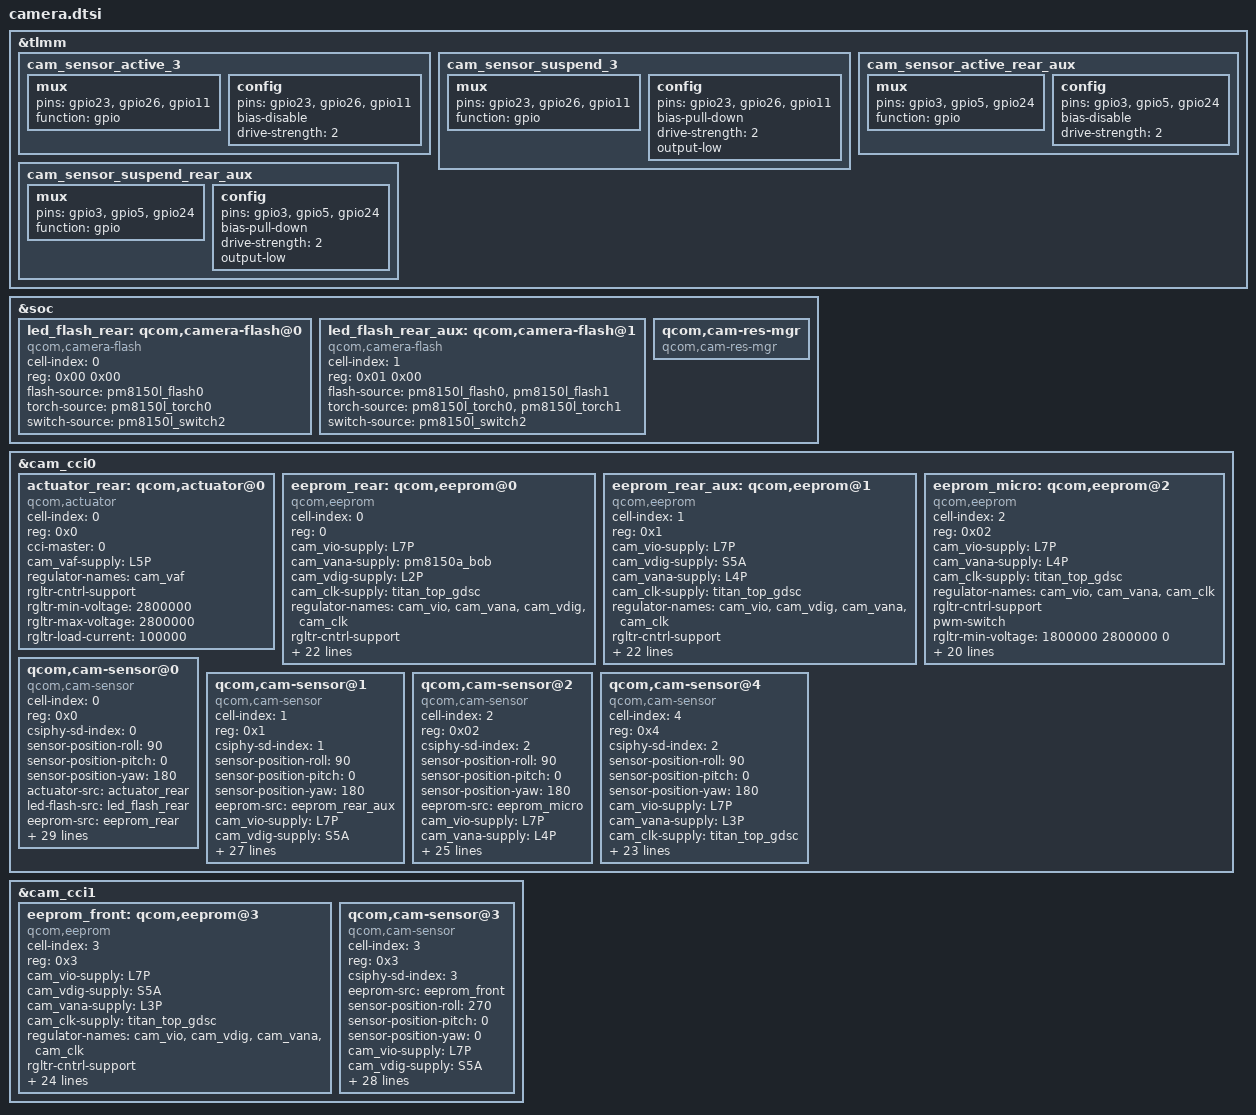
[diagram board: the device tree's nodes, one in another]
#include <dt-bindings/clock/qcom,camcc-lito.h>

&tlmm {
//20M
	/delete-node/ cam_sensor_active_3;
	/delete-node/ cam_sensor_suspend_3;
	/delete-node/ cam_sensor_active_rear_aux;
	/delete-node/ cam_sensor_suspend_rear_aux;
	cam_sensor_active_3: cam_sensor_active_3 {
		/* RESET FRONT */
		mux {
			pins = "gpio23", "gpio26", "gpio11";
			function = "gpio";
		};

		config {
			pins = "gpio23", "gpio26", "gpio11";
			bias-disable; /* No PULL */
			drive-strength = <2>; /* 2 MA */
		};
	};

	cam_sensor_suspend_3: cam_sensor_suspend_3 {
		/* RESET FRONT */
		mux {
			pins = "gpio23", "gpio26", "gpio11";
			function = "gpio";
		};

		config {
			pins = "gpio23", "gpio26", "gpio11";
			bias-pull-down; /* PULL DOWN */
			drive-strength = <2>; /* 2 MA */
			output-low;
		};
	};
//8M
		cam_sensor_active_rear_aux: cam_sensor_active_rear_aux {
			/* RESET REARAUX,DVDD ELDO */
			mux {
				pins = "gpio3", "gpio5", "gpio24";
				function = "gpio";
			};

			config {
				pins = "gpio3", "gpio5", "gpio24";
				bias-disable; /* No PULL */
				drive-strength = <2>; /* 2 MA */
			};
		};

		cam_sensor_suspend_rear_aux: cam_sensor_suspend_rear_aux {
			/* RESET REARAUX,DVDD ELDO */
			mux {
				pins = "gpio3", "gpio5", "gpio24";
				function = "gpio";
			};

			config {
				pins = "gpio3", "gpio5", "gpio24";
				bias-pull-down; /* PULL DOWN */
				drive-strength = <2>; /* 2 MA */
				output-low;
			};
		};
};

&soc {
	led_flash_rear: qcom,camera-flash@0 {
		cell-index = <0>;
		reg = <0x00 0x00>;
		compatible = "qcom,camera-flash";
		flash-source = <&pm8150l_flash0>;
		torch-source = <&pm8150l_torch0>;
		switch-source = <&pm8150l_switch2>;
	};

	led_flash_rear_aux: qcom,camera-flash@1 {
		cell-index = <1>;
		reg = <0x01 0x00>;
		compatible = "qcom,camera-flash";
		flash-source = <&pm8150l_flash0 &pm8150l_flash1>;
		torch-source = <&pm8150l_torch0 &pm8150l_torch1>;
		switch-source = <&pm8150l_switch2>;
	};

	qcom,cam-res-mgr {
		compatible = "qcom,cam-res-mgr";
		status = "ok";
	};
	
};

&cam_cci0 {
	actuator_rear: qcom,actuator@0 {
		cell-index = <0>;
		reg = <0x0>;
		compatible = "qcom,actuator";
		cci-master = <0>;
		cam_vaf-supply = <&L5P>;
		regulator-names = "cam_vaf";
		rgltr-cntrl-support;
		rgltr-min-voltage = <2800000>;
		rgltr-max-voltage = <2800000>;
		rgltr-load-current = <100000>;
		status = "ok";
	};

	eeprom_rear: qcom,eeprom@0 {
		cell-index = <0>;
		reg = <0>;
		compatible = "qcom,eeprom";
		cam_vio-supply = <&L7P>;
		cam_vana-supply = <&pm8150a_bob>;
		cam_vdig-supply = <&L2P>;
		cam_clk-supply = <&titan_top_gdsc>;
		regulator-names = "cam_vio","cam_vana","cam_vdig",
			"cam_clk";
		rgltr-cntrl-support;
		pwm-switch;
		rgltr-min-voltage = <1800000 3008000 1104000 0>;
		rgltr-max-voltage = <1800000 3960000 1104000 0>;
		rgltr-load-current = <0 2000000 105000 0>;
		gpio-no-mux = <0>;
		pinctrl-names = "cam_default", "cam_suspend";
		pinctrl-0 = <&cam_sensor_mclk0_active
				&cam_sensor_active_rear>;
		pinctrl-1 = <&cam_sensor_mclk0_suspend
				&cam_sensor_suspend_rear>;
		gpios = <&tlmm 13 0>,
			<&tlmm 30 0>,
			<&tlmm 0 0>,
			<&tlmm 63 0>;
		gpio-reset = <1>;
		gpio-vana = <2>;
		gpio-custom1 = <3>;
		gpio-req-tbl-num = <0 1 2 3>;
		gpio-req-tbl-flags = <1 0 0 0>;
		gpio-req-tbl-label = "CAMIF_MCLK0",
					"CAM_RESET0",
					"CAM_VANA0",
					"CAM_CUSTOM1";
		sensor-mode = <0>;
		cci-master = <0>;
		status = "ok";
		clocks = <&camcc CAM_CC_MCLK0_CLK>;
		clock-names = "cam_clk";
		clock-cntl-level = "turbo";
		clock-rates = <24000000>;
	};
	eeprom_rear_aux: qcom,eeprom@1 {
		cell-index = <1>;
		reg = <0x1>;
		compatible = "qcom,eeprom";
		cam_vio-supply = <&L7P>;
		cam_vdig-supply = <&S5A>;
		cam_vana-supply = <&L4P>;
		cam_clk-supply = <&titan_top_gdsc>;
		regulator-names ="cam_vio","cam_vdig","cam_vana","cam_clk";
		rgltr-cntrl-support;
		pwm-switch;
		rgltr-min-voltage =  <1800000 2000000 2800000 0>;
		rgltr-max-voltage =  <1800000 2000000 2800000 0>;
		rgltr-load-current = <120000  120000  80000   0>;
		gpio-no-mux = <0>;
		pinctrl-names = "cam_default", "cam_suspend";
		pinctrl-0 = <&cam_sensor_mclk1_active
				&cam_sensor_active_rear_aux>;
		pinctrl-1 = <&cam_sensor_mclk1_suspend
				&cam_sensor_suspend_rear_aux>;
		gpios = <&tlmm 14 0>,
			<&tlmm  3 0>,
			<&tlmm  5 0>,
			<&tlmm 24 0>;
		gpio-standby = <1>;
		gpio-vdig = <2>;
		gpio-reset = <3>;
		gpio-req-tbl-num = <0 1 2 3>;
		gpio-req-tbl-flags = <1 0 0 0>;
		gpio-req-tbl-label = "CAMIF_MCLK1",
		"CAM_STANDBY1",
		"CAM_VDIG1",
		"CAM_RESET1";
		sensor-mode = <0>;
		cci-master = <0>;
		status = "ok";
		clocks = <&camcc CAM_CC_MCLK1_CLK>;
		clock-names = "cam_clk";
		clock-cntl-level = "turbo";
		clock-rates = <19200000>;
	};
	eeprom_micro: qcom,eeprom@2 {
		cell-index = <2>;
		reg = <0x02>;
		compatible = "qcom,eeprom";
		cam_vio-supply = <&L7P>;
		cam_vana-supply = <&L4P>;
		cam_clk-supply = <&titan_top_gdsc>;
		regulator-names = "cam_vio", 
						  "cam_vana",
			              "cam_clk";
		rgltr-cntrl-support;
		pwm-switch;
		rgltr-min-voltage = <1800000 2800000 0>;
		rgltr-max-voltage = <1800000 2800000 0>;
		rgltr-load-current = <120000 80000 0>;
		gpio-no-mux = <0>;
		pinctrl-names = "cam_default", "cam_suspend";
		pinctrl-0 = <&cam_sensor_mclk4_active
				 &cam_sensor_active_rear_aux2>;
		pinctrl-1 = <&cam_sensor_mclk4_suspend
				 &cam_sensor_suspend_rear_aux2>;
		gpios = <&tlmm 25 0>,
			    <&tlmm 21 0>,
				<&tlmm 68 0>;
		gpio-reset = <1>;
		gpio-standby = <2>;
		gpio-req-tbl-num = <0 1 2>;
		gpio-req-tbl-flags = <1 0 0>;
		gpio-req-tbl-label = "CAMIF_MCLK2",
							  "CAM_RESET2",
							  "CAM_STANDBY2";
		sensor-mode = <0>;
		cci-device = <0>;
		cci-master = <1>;
		status = "ok";
		clocks = <&camcc CAM_CC_MCLK4_CLK>;
		clock-names = "cam_clk";
		clock-cntl-level = "turbo";
		clock-rates = <19200000>;
	};
	qcom,cam-sensor@0 {
		cell-index = <0>;
		compatible = "qcom,cam-sensor";
		reg = <0x0>;
		csiphy-sd-index = <0>;
		sensor-position-roll = <90>;
		sensor-position-pitch = <0>;
		sensor-position-yaw = <180>;
		actuator-src = <&actuator_rear>;
		led-flash-src = <&led_flash_rear>;
		eeprom-src = <&eeprom_rear>;
		cam_vio-supply = <&L7P>;
		cam_vana-supply = <&pm8150a_bob>;
		cam_vdig-supply = <&L2P>;
		cam_clk-supply = <&titan_top_gdsc>;
		regulator-names = "cam_vio","cam_vana","cam_vdig",
			"cam_clk";
		rgltr-cntrl-support;
		pwm-switch;
		rgltr-min-voltage = <1800000 3008000 1104000 0>;
		rgltr-max-voltage = <1800000 3960000 1104000 0>;
		rgltr-load-current = <0 2000000 105000 0>;
		gpio-no-mux = <0>;
		pinctrl-names = "cam_default", "cam_suspend";
		pinctrl-0 = <&cam_sensor_mclk0_active
				&cam_sensor_active_rear>;
		pinctrl-1 = <&cam_sensor_mclk0_suspend
				&cam_sensor_suspend_rear>;
		gpios = <&tlmm 13 0>,
			<&tlmm 30 0>,
			<&tlmm 0 0>,
			<&tlmm 63 0>;
		gpio-reset = <1>;
		gpio-vana = <2>;
		gpio-custom1 = <3>;
		gpio-req-tbl-num = <0 1 2 3>;
		gpio-req-tbl-flags = <1 0 0 0>;
		gpio-req-tbl-label = "CAMIF_MCLK0",
					"CAM_RESET0",
					"CAM_VANA0",
					"CAM_CUSTOM1";
		sensor-mode = <0>;
		cci-master = <0>;
		status = "ok";
		clocks = <&camcc CAM_CC_MCLK0_CLK>;
		clock-names = "cam_clk";
		clock-cntl-level = "turbo";
		clock-rates = <19200000>;
	};

	qcom,cam-sensor@1 {
		cell-index = <1>;
		compatible = "qcom,cam-sensor";
		reg = <0x1>;
		csiphy-sd-index = <1>;
		sensor-position-roll = <90>;
		sensor-position-pitch = <0>;
		sensor-position-yaw = <180>;
		eeprom-src = <&eeprom_rear_aux>;
		//led-flash-src = <&led_flash_rear_aux>;
		//actuator-src = <&actuator_rear_aux>;
		cam_vio-supply = <&L7P>;
		cam_vdig-supply = <&S5A>; 
		cam_vana-supply = <&L4P>; 
		cam_clk-supply = <&titan_top_gdsc>;
		regulator-names ="cam_vio","cam_vdig","cam_vana","cam_clk";
		rgltr-cntrl-support;
		pwm-switch;
		rgltr-min-voltage =  <1800000 2000000 2800000 0>;
		rgltr-max-voltage =  <1800000 2000000 2800000 0>;
		rgltr-load-current = <120000  120000  80000   0>;
		gpio-no-mux = <0>;
		pinctrl-names = "cam_default", "cam_suspend";
		pinctrl-0 = <&cam_sensor_mclk1_active
				&cam_sensor_active_rear_aux>;
		pinctrl-1 = <&cam_sensor_mclk1_suspend
				&cam_sensor_suspend_rear_aux>;
		gpios = <&tlmm 14 0>,
			<&tlmm  3 0>,
			<&tlmm  5 0>,
			<&tlmm 24 0>;
		gpio-standby = <1>;		
		gpio-vdig = <2>;
		gpio-reset = <3>;
		gpio-req-tbl-num = <0 1 2 3>;
		gpio-req-tbl-flags = <1 0 0 0>;
		gpio-req-tbl-label = "CAMIF_MCLK1",
		"CAM_STANDBY1",
		"CAM_VDIG1",
		"CAM_RESET1";
		sensor-mode = <0>;
		cci-master = <0>;
		status = "ok";
		clocks = <&camcc CAM_CC_MCLK1_CLK>;
		clock-names = "cam_clk";
		clock-cntl-level = "turbo";
		clock-rates = <19200000>;
	};
	qcom,cam-sensor@2 {
		cell-index = <2>;
		compatible = "qcom,cam-sensor";
		reg = <0x02>;
		csiphy-sd-index = <2>;
		sensor-position-roll = <90>;
		sensor-position-pitch = <0>;
		sensor-position-yaw = <180>;
		eeprom-src = <&eeprom_micro>;
		cam_vio-supply = <&L7P>;
		cam_vana-supply = <&L4P>;		
		cam_clk-supply = <&titan_top_gdsc>;
		regulator-names = "cam_vio", 
						  "cam_vana",
			              "cam_clk";
		rgltr-cntrl-support;
		pwm-switch;
		rgltr-min-voltage = <1800000 2800000 0>;
		rgltr-max-voltage = <1800000 2800000 0>;
		rgltr-load-current = <120000 80000 0>;
		gpio-no-mux = <0>;
		pinctrl-names = "cam_default", "cam_suspend";
		pinctrl-0 = <&cam_sensor_mclk4_active
				 &cam_sensor_active_rear_aux2>;
		pinctrl-1 = <&cam_sensor_mclk4_suspend
				 &cam_sensor_suspend_rear_aux2>;
		gpios = <&tlmm 25 0>,
			    <&tlmm 21 0>,
				<&tlmm 68 0>;
		gpio-reset = <1>;
		gpio-standby = <2>;
		gpio-req-tbl-num = <0 1 2>;
		gpio-req-tbl-flags = <1 0 0>;
		gpio-req-tbl-label = "CAMIF_MCLK2",
							  "CAM_RESET2",
							  "CAM_STANDBY2";
		sensor-mode = <0>;
		cci-device = <0>;
		cci-master = <1>;
		status = "ok";
		clocks = <&camcc CAM_CC_MCLK4_CLK>;
		clock-names = "cam_clk";
		clock-cntl-level = "turbo";
		clock-rates = <19200000>;
	};
	qcom,cam-sensor@4{
		cell-index = <4>;
		compatible = "qcom,cam-sensor";
		reg = <0x4>;
		csiphy-sd-index = <2>;
		sensor-position-roll = <90>;
		sensor-position-pitch = <0>;
		sensor-position-yaw = <180>;
		cam_vio-supply = <&L7P>;
		cam_vana-supply = <&L3P>;
		cam_clk-supply = <&titan_top_gdsc>;
		regulator-names = "cam_vio", "cam_vana", "cam_clk";
		rgltr-cntrl-support;
		pwm-switch;
		rgltr-min-voltage = <1800000 2800000 0>;
		rgltr-max-voltage = <1800000 2800000 0>;
		rgltr-load-current = <0 180000 0>;
		gpio-no-mux = <0>;
		pinctrl-names = "cam_default", "cam_suspend";
		pinctrl-0 = <&cam_sensor_mclk2_active
				 &cam_sensor_active_front>;
		pinctrl-1 = <&cam_sensor_mclk2_suspend
				 &cam_sensor_suspend_front>;
		gpios = <&tlmm 15 0>,
			<&tlmm 32 0>;
		gpio-reset = <1>;
		gpio-req-tbl-num = <0 1>;
		gpio-req-tbl-flags = <1 0>;
		gpio-req-tbl-label = "CAMIF_MCLK2",
					"CAM_RESET2";
		sensor-position = <0>;
		sensor-mode = <0>;
		cci-device = <1>;
		cci-master = <1>;
		status = "ok";
		clocks = <&camcc CAM_CC_MCLK2_CLK>;
		clock-names = "cam_clk";
		clock-cntl-level = "turbo";
		clock-rates = <19200000>;
	};
};

&cam_cci1 {
	eeprom_front: qcom,eeprom@3 {
		cell-index = <3>;
		compatible = "qcom,eeprom";
		reg = <0x3>;
		cam_vio-supply = <&L7P>;
		cam_vdig-supply = <&S5A>;
		cam_vana-supply = <&L3P>;
		cam_clk-supply = <&titan_top_gdsc>;
		regulator-names = "cam_vio","cam_vdig", "cam_vana",
			"cam_clk";
		rgltr-cntrl-support;
		pwm-switch;
		rgltr-min-voltage = <1800000 2000000 2800000 0>;
		rgltr-max-voltage = <1800000 2000000 2800000 0>;
		rgltr-load-current = <0  120000  80000  0>;
		gpio-no-mux = <0>;
		pinctrl-names = "cam_default", "cam_suspend";
		pinctrl-0 = <&cam_sensor_mclk3_active
				 &cam_sensor_active_3>;
		pinctrl-1 = <&cam_sensor_mclk3_suspend
				 &cam_sensor_suspend_3>;
		gpios = <&tlmm 16 0>,
			<&tlmm 23 0>,
			<&tlmm 26 0>,
			<&tlmm 11 0>;
		gpio-reset = <1>;
		gpio-vdig = <2>;
		gpio-standby = <3>;
		gpio-req-tbl-num = <0 1 2 3>;
		gpio-req-tbl-flags = <1 0 0 0>;
		gpio-req-tbl-label = "CAMIF_MCLK3",
					"CAM_RESET3",
					"CAM_VDIG3",
					"CAM_STANDBY3";
		sensor-position = <1>;
		sensor-mode = <0>;
		cci-device = <1>;
		cci-master = <0>;
		status = "ok";
		clocks = <&camcc CAM_CC_MCLK3_CLK>;
		clock-names = "cam_clk";
		clock-cntl-level = "turbo";
		clock-rates = <19200000>;
	};
    qcom,cam-sensor@3 {
		cell-index = <3>;
		compatible = "qcom,cam-sensor";
		reg = <0x3>;
		csiphy-sd-index = <3>;
		eeprom-src = <&eeprom_front>;
		sensor-position-roll = <270>;
		sensor-position-pitch = <0>;
		sensor-position-yaw = <0>;
		cam_vio-supply = <&L7P>; 
		cam_vdig-supply = <&S5A>; 
		cam_vana-supply = <&L3P>; 
		cam_clk-supply = <&titan_top_gdsc>;
		regulator-names = "cam_vio","cam_vdig", "cam_vana",   
			"cam_clk";
		rgltr-cntrl-support;
		pwm-switch;
		rgltr-min-voltage = <1800000 2000000 2800000 0>; 
		rgltr-max-voltage = <1800000 2000000 2800000 0>;
		rgltr-load-current = <0  120000  80000  0>;
		gpio-no-mux = <0>;
		pinctrl-names = "cam_default", "cam_suspend";
		pinctrl-0 = <&cam_sensor_mclk3_active
				 &cam_sensor_active_3>;
		pinctrl-1 = <&cam_sensor_mclk3_suspend
				 &cam_sensor_suspend_3>;
		gpios = <&tlmm 16 0>,
			<&tlmm 23 0>,
			<&tlmm 26 0>,
			<&tlmm 11 0>;
		gpio-reset = <1>;
		gpio-vdig = <2>;
		gpio-standby = <3>;
		gpio-req-tbl-num = <0 1 2 3>;
		gpio-req-tbl-flags = <1 0 0 0>;
		gpio-req-tbl-label = "CAMIF_MCLK3",
					"CAM_RESET3",
					"CAM_VDIG3",
					"CAM_STANDBY3";
		sensor-mode = <0>;
		cci-device = <1>;
		cci-master = <0>;
		status = "ok";
		clocks = <&camcc CAM_CC_MCLK3_CLK>;
		clock-names = "cam_clk";
		clock-cntl-level = "turbo";
		clock-rates = <19200000>;
	};
};
